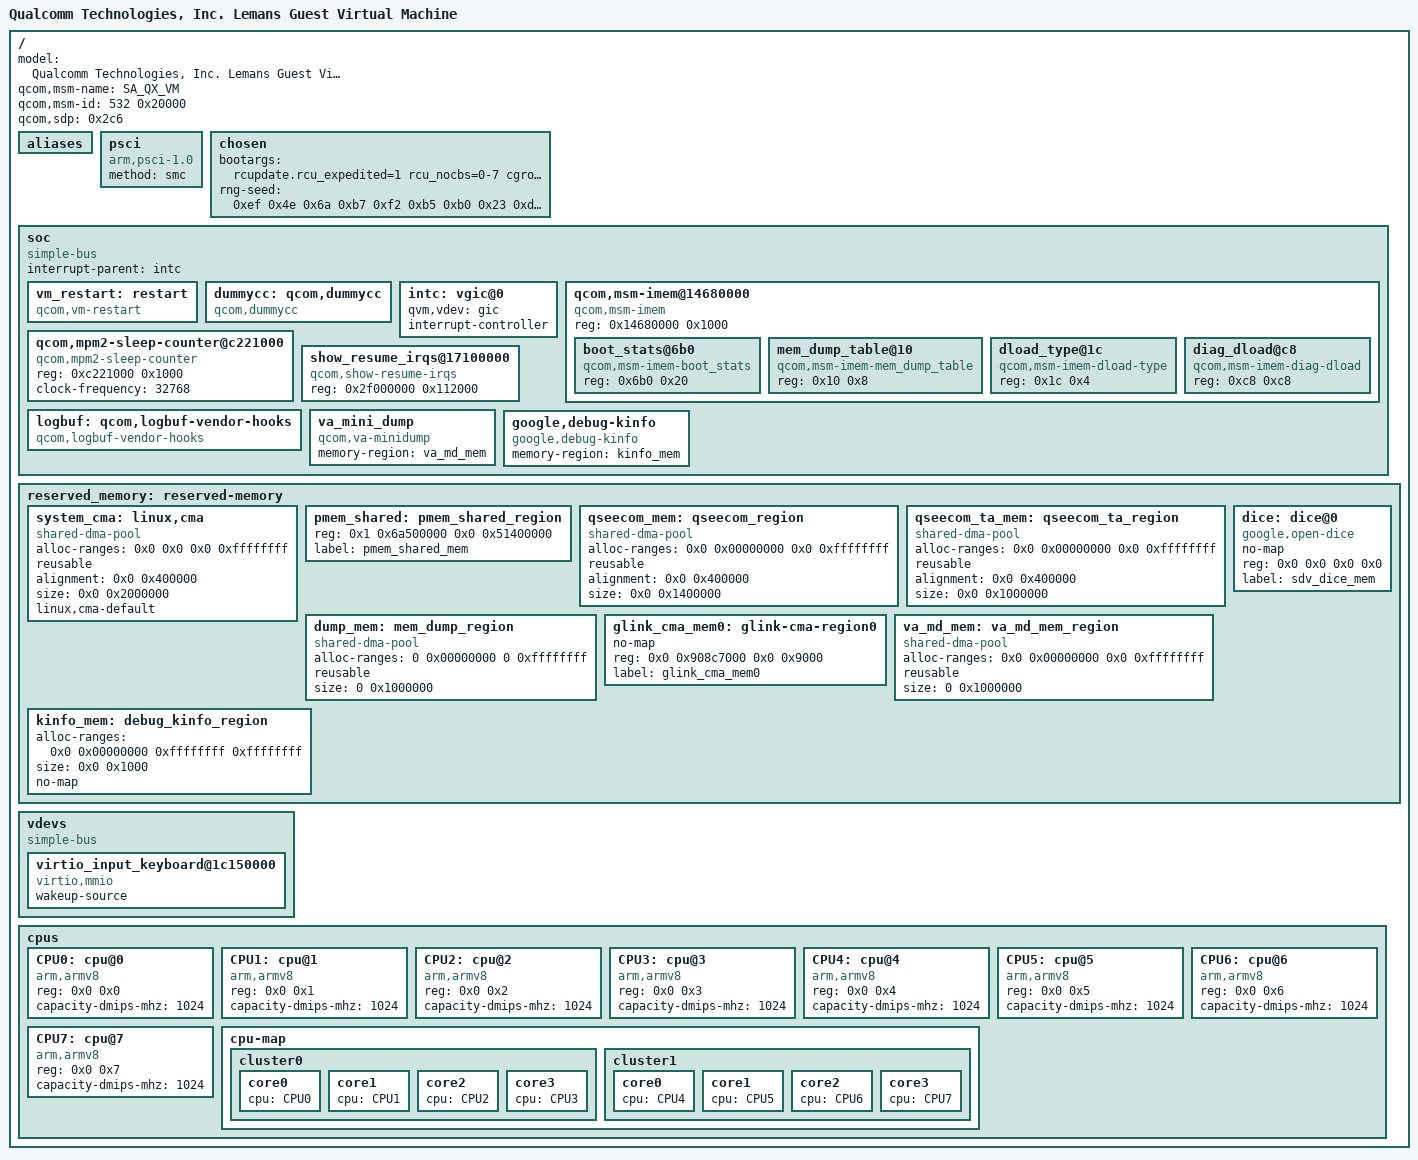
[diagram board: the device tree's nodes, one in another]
// SPDX-License-Identifier: BSD-3-Clause
/*
 * Copyright (c) Qualcomm Technologies, Inc. and/or its subsidiaries.
 */

/ {
	model = "Qualcomm Technologies, Inc. Lemans Guest Virtual Machine";
	qcom,msm-name  = "SA_QX_VM";
	qcom,msm-id = <532 0x20000>;
	qcom,sdp = <0x2c6>;

	aliases {
	};

	psci {
		compatible = "arm,psci-1.0";
		method = "smc";
	};

	chosen {
		bootargs = "rcupdate.rcu_expedited=1 rcu_nocbs=0-7 cgroup.memory=nokmem,nosocket kpti=0 arm64.nopauth kasan=off";
		rng-seed = <0xef 0x4e 0x6a 0xb7 0xf2 0xb5 0xb0 0x23 0xdf 0xa7 0xeb 0x2b 0x44 0x40 0x11 0x7d 0x5c 0xbb 0xf1 0x21 0x5d 0x82 0x1a 0x4a 0x04 0xf5 0x93 0x8a 0x7f 0x2a 0xee 0x56>;
	};

	soc: soc { };

	reserved_memory: reserved-memory {
		#address-cells = <2>;
		#size-cells = <2>;
		ranges;

		system_cma: linux,cma {
			compatible = "shared-dma-pool";
			alloc-ranges = <0x0 0x0 0x0 0xffffffff>;
			reusable;
			alignment = <0x0 0x400000>;
			size = <0x0 0x2000000>;
			linux,cma-default;
		};

		pmem_shared: pmem_shared_region {
			reg = <0x1 0x6a500000 0x0 0x51400000>;
			label = "pmem_shared_mem";
		};

		qseecom_mem: qseecom_region {
			compatible = "shared-dma-pool";
			alloc-ranges = <0x0 0x00000000 0x0 0xffffffff>;
			reusable;
			alignment = <0x0 0x400000>;
			size = <0x0 0x1400000>;
		};

		qseecom_ta_mem: qseecom_ta_region {
			compatible = "shared-dma-pool";
			alloc-ranges = <0x0 0x00000000 0x0 0xffffffff>;
			reusable;
			alignment = <0x0 0x400000>;
			size = <0x0 0x1000000>;
		};

		dump_mem: mem_dump_region {
			compatible = "shared-dma-pool";
			alloc-ranges = <0 0x00000000 0 0xffffffff>;
			reusable;
			size = <0 0x1000000>;
		};
	};

	vdevs {
		compatible = "simple-bus";
		virtio_input_keyboard@1c150000 {
			compatible = "virtio,mmio";
			wakeup-source;
		};
	};


	cpus {
		#address-cells = <2>;
		#size-cells = <0>;

		CPU0: cpu@0 {
			device_type = "cpu";
			compatible = "arm,armv8";
			reg = <0x0 0x0>;
			capacity-dmips-mhz = <1024>;
		};

		CPU1: cpu@1 {
			device_type = "cpu";
			compatible = "arm,armv8";
			reg = <0x0 0x1>;
			capacity-dmips-mhz = <1024>;
		};

		CPU2: cpu@2 {
			device_type = "cpu";
			compatible = "arm,armv8";
			reg = <0x0 0x2>;
			capacity-dmips-mhz = <1024>;
		};

		CPU3: cpu@3 {
			device_type = "cpu";
			compatible = "arm,armv8";
			reg = <0x0 0x3>;
			capacity-dmips-mhz = <1024>;
		};

		CPU4: cpu@4 {
			device_type = "cpu";
			compatible = "arm,armv8";
			reg = <0x0 0x4>;
			capacity-dmips-mhz = <1024>;
		};

		CPU5: cpu@5 {
			device_type = "cpu";
			compatible = "arm,armv8";
			reg = <0x0 0x5>;
			capacity-dmips-mhz = <1024>;
		};

		CPU6: cpu@6 {
			device_type = "cpu";
			compatible = "arm,armv8";
			reg = <0x0 0x6>;
			capacity-dmips-mhz = <1024>;
		};

		CPU7: cpu@7 {
			device_type = "cpu";
			compatible = "arm,armv8";
			reg = <0x0 0x7>;
			capacity-dmips-mhz = <1024>;
		};

		cpu-map {
			cluster0 {
				core0 {
					cpu = <&CPU0>;
				};

				core1 {
					cpu = <&CPU1>;
				};

				core2 {
					cpu = <&CPU2>;
				};

				core3 {
					cpu = <&CPU3>;
				};
			};

			cluster1 {
				core0 {
					cpu = <&CPU4>;
				};

				core1 {
					cpu = <&CPU5>;
				};

				core2 {
					cpu = <&CPU6>;
				};

				core3 {
					cpu = <&CPU7>;
				};
			};
		};
	};
};

&reserved_memory {
	glink_cma_mem0: glink-cma-region0 {
		no-map;
		reg = <0x0 0x908c7000 0x0 0x9000>;
		label = "glink_cma_mem0";
	};

	dice: dice@0 {
		compatible = "google,open-dice";
		no-map;
		reg = <0x0 0x0 0x0 0x0>;
		label = "sdv_dice_mem";
	};

	va_md_mem: va_md_mem_region {
		compatible = "shared-dma-pool";
		alloc-ranges = <0x0 0x00000000 0x0 0xffffffff>;
		reusable;
		size = <0 0x1000000>;
	};

	kinfo_mem: debug_kinfo_region {
		alloc-ranges = <0x0 0x00000000 0xffffffff 0xffffffff>;
		size = <0x0 0x1000>;
		no-map;
	};
};

&soc {
	#address-cells = <1>;
	#size-cells = <1>;
	interrupt-parent = <&intc>;
	ranges = <0x0 0x0 0x0 0xffffffff>;
	compatible = "simple-bus";

	vm_restart: restart {
		compatible = "qcom,vm-restart";
		status = "ok";
	};

	dummycc: qcom,dummycc {
		compatible = "qcom,dummycc";
		#clock-cells = <1>;
		#reset-cells = <1>;
	};

	intc: vgic@0 {
		qvm,vdev = "gic";
		#interrupt-cells = <3>;
		interrupt-controller;
	};

	qcom,msm-imem@14680000 {
		compatible = "qcom,msm-imem";
		reg = <0x14680000 0x1000>;
		ranges = <0x0 0x14680000 0x1000>;
		#address-cells = <1>;
		#size-cells = <1>;

		boot_stats@6b0 {
			compatible = "qcom,msm-imem-boot_stats";
			reg = <0x6b0 0x20>;
		};

		mem_dump_table@10 {
			compatible = "qcom,msm-imem-mem_dump_table";
			reg = <0x10 0x8>;
		};

		dload_type@1c {
			compatible = "qcom,msm-imem-dload-type";
			reg = <0x1c 0x4>;
		};

		diag_dload@c8 {
			compatible = "qcom,msm-imem-diag-dload";
			reg = <0xc8 0xc8>;
		};
	};

	qcom,mpm2-sleep-counter@c221000 {
		compatible = "qcom,mpm2-sleep-counter";
		reg = <0xc221000 0x1000>;
		clock-frequency = <32768>;
	};

	show_resume_irqs@17100000 {
		compatible = "qcom,show-resume-irqs";
		reg = <0x2f000000 0x112000>;
	};

	logbuf: qcom,logbuf-vendor-hooks {
		compatible = "qcom,logbuf-vendor-hooks";
	};

	va_mini_dump {
		compatible = "qcom,va-minidump";
		memory-region = <&va_md_mem>;
	};

	google,debug-kinfo {
		compatible = "google,debug-kinfo";
		memory-region = <&kinfo_mem>;
	};
};
